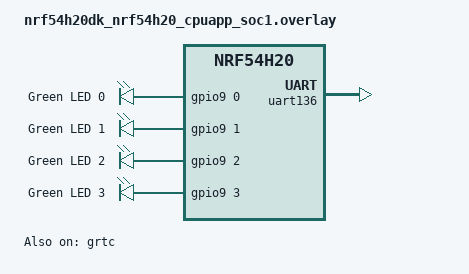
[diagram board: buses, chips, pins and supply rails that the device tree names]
/*
 * Copyright (c) 2023 Nordic Semiconductor ASA
 *
 * SPDX-License-Identifier: LicenseRef-Nordic-5-Clause
 */

 /{
	allocatable_ram {
		#address-cells = <1>;
		#size-cells = <1>;

		/* Allow to use defined RAM3x
		 * region by App and cores owned by App.
		 */
		ram3x_app_ppr: memory@2fc00000 {
			compatible = "nordic,allocatable-ram";
			reg = <0x2fc00000 DT_SIZE_K(32)>;
			perm-read;
			perm-write;
		};
	};

	/delete-node/ leds;

	leds0 {
		compatible = "gpio-leds";
		led0: led_0 {
			gpios = < &gpio9 0 GPIO_ACTIVE_HIGH >;
			label = "Green LED 0";
		};
	};

	leds1 {
		compatible = "gpio-leds";
		led1: led_1 {
			gpios = < &gpio9 1 GPIO_ACTIVE_HIGH >;
			label = "Green LED 1";
		};
	};

	leds2 {
		compatible = "gpio-leds";
		led2: led_2 {
			gpios = < &gpio9 2 GPIO_ACTIVE_HIGH >;
			label = "Green LED 2";
		};
	};

	leds3 {
		compatible = "gpio-leds";
		led3: led_3 {
			gpios = < &gpio9 3 GPIO_ACTIVE_HIGH >;
			label = "Green LED 3";
		};
	};

	chosen {
		zephyr,console = &uart136;
	};
};

/* ram3x_cpuapp buffer is used by App core UART driver. */
&ram3x_cpuapp {
	status = "okay";
};

&uart136 {
	status = "okay";
	memory-regions = <&ram3x_cpuapp>;
};

&grtc {
	status = "okay";
};

&gpio9 {
	status = "okay";
};
